# AT32F423 register map
Vendor: Keil; Series: AT32F423; File version: 1.0
CPU: CM4 r0p1, little endian, no MPU, FPU, 4 interrupt priority bits
Registers are 32-bit, read-write, reset 0x0 unless marked. A register's access mark holds for its fields unless they carry their own. Offsets are from the block's base; [hi:lo] are bit positions; {n}, {i} and the like mark numbered series; 'fields as' and 'values as' point back to an identical list.

## EXINT
Base 0x40013C00
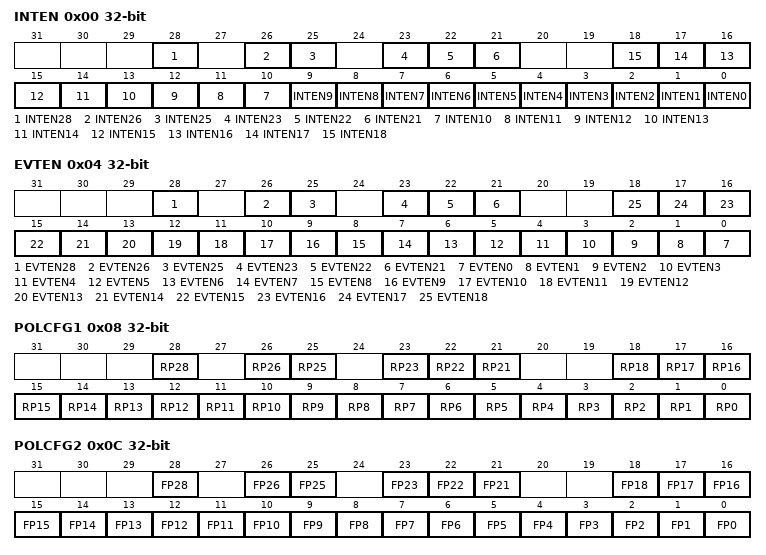
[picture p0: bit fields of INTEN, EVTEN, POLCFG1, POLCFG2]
0x00 INTEN — Interrupt enable register
  [28] INTEN28 — Interrupt enable or disable on line 28
  [26] INTEN26 — Interrupt enable or disable on line 26
  [25] INTEN25 — Interrupt enable or disable on line 25
  [23] INTEN23 — Interrupt enable or disable on line 23
  [22] INTEN22 — Interrupt enable or disable on line 22
  [21] INTEN21 — Interrupt enable or disable on line 21
  [n] INTEN{n} (n=0..18) — Interrupt enable or disable on line {n}
0x04 EVTEN — Event enable register
  [28] EVTEN28 — Event enable or disable on line 28
  [26] EVTEN26 — Event enable or disable on line 26
  [25] EVTEN25 — Event enable or disable on line 25
  [23] EVTEN23 — Event enable or disable on line 23
  [22] EVTEN22 — Event enable or disable on line 22
  [21] EVTEN21 — Event enable or disable on line 21
  [n] EVTEN{n} (n=0..18) — Event enable or disable on line {n}
0x08 POLCFG1 — Rising polarity configuration register
  [28] RP28 — Rising polarity configuration bit of line 28
  [26] RP26 — Rising polarity configuration bit of line 26
  [25] RP25 — Rising polarity configuration bit of line 25
  [23] RP23 — Rising polarity configuration bit of line 23
  [22] RP22 — Rising polarity configuration bit of line 22
  [21] RP21 — Rising polarity configuration bit of line 21
  [n] RP{n} (n=7..18) — Rising polarity configuration bit of line {n}
  [6] RP6 — Rising polarity configuration bit of linee 6
  [n] RP{n} (n=0..5) — Rising polarity configuration bit of line {n}
0x0C POLCFG2 — Falling polarity configuration register
  [28] FP28 — Falling polarity event configuration bit of line 28
  [26] FP26 — Falling polarity event configuration bit of line 26
  [25] FP25 — Falling polarity event configuration bit of line 25
  [23] FP23 — Falling polarity event configuration bit of line 23
  [22] FP22 — Falling polarity event configuration bit of line 22
  [21] FP21 — Falling polarity event configuration bit of line 21
  [n] FP{n} (n=0..18) — Falling polarity event configuration bit of line {n}
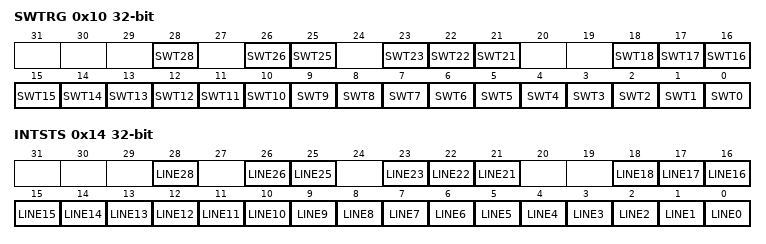
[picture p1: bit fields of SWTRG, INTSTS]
0x10 SWTRG — Software triggle register
  [28] SWT28 — Software triggle on line 28
  [26] SWT26 — Software triggle on line 26
  [25] SWT25 — Software triggle on line 25
  [23] SWT23 — Software triggle on line 23
  [22] SWT22 — Software triggle on line 22
  [21] SWT21 — Software triggle on line 21
  [n] SWT{n} (n=0..18) — Software triggle on line {n}
0x14 INTSTS — Interrupt status register
  [28] LINE28 — Line 28 state bit
  [26] LINE26 — Line 26 state bit
  [25] LINE25 — Line 25 state bit
  [23] LINE23 — Line 23 state bit
  [22] LINE22 — Line 22 state bit
  [21] LINE21 — Line 21 state bit
  [n] LINE{n} (n=0..18) — Line {n} state bit

## WDT — Watchdog
Base 0x40003000
0x00 CMD wo — Command register
  [15:0] CMD
    0x5555=Unlock write-protected WDT_DIV and WDT_RLD; 0xAAAA=Reload counter; 0xCCCC=Enable WDT. If the hardware watchdog has been enabled, ignore this operation.
0x04 DIV — Division register
  [2:0] DIV — Division divider
    0=LICK divided by 4; 1=LICK divided by 8; 2=LICK divided by 16; 3=LICK divided by 32; 4=LICK divided by 64; 5=LICK divided by 128; 6=LICK divided by 256; 7=div256_2 (LICK divided by 256)
0x08 RLD reset 0xFFF — Reload register
  [11:0] RLD — Reload value
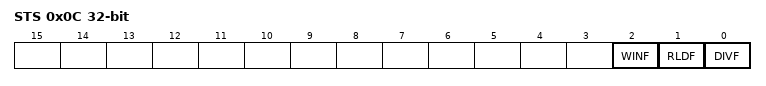
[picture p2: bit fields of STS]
0x0C STS ro — Status register
  [2] WINF — Window value update complete flag
    0=Complete (Reload value update complete); 1=InProgress (Reload value update is in process)
  [1] RLDF — Reload value update complete flag
    values as WINF
  [0] DIVF — Division value update complete flag
    0=Complete (Division value update complete); 1=InProgress (Division value update is in process)
0x10 WIN ro reset 0xFFF — Window register
  [11:0] WIN — Window value
